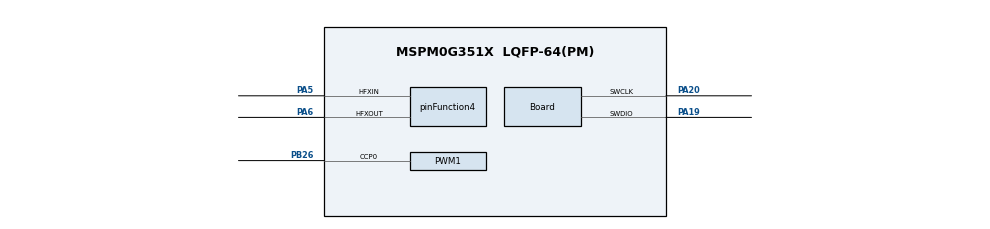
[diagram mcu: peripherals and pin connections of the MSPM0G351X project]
/**
 * @cliArgs --device "MSPM0G351X" --part "Default" --package "LQFP-64(PM)" --product "mspm0_sdk@2.05.01.01"
 * @versions {"tool":"1.24.0+4110"}
 */
const PWM    = scripting.addModule("/ti/driverlib/PWM", {}, false);
const PWM1   = PWM.addInstance();
const SYSCTL = scripting.addModule("/ti/driverlib/SYSCTL");
const TIMER  = scripting.addModule("/ti/driverlib/TIMER", {}, false);
const TIMER1 = TIMER.addInstance();

/* 80 MHz clock */
SYSCTL.forceDefaultClkConfig = true;
SYSCTL.clockTreeEn           = true;
scripting.suppress("For best practices when the CPUCLK is running at 32MHz and above, clear the flash status bit using DL_FlashCTL_executeClearStatus\\(\\) before executing any flash operation\\. Otherwise there may be false positives\\.", SYSCTL);
const divider9       = system.clockTree["UDIV"];
divider9.divideValue = 2;
const multiplier2         = system.clockTree["PLL_QDIV"];
multiplier2.multiplyValue = 4;
const mux4       = system.clockTree["EXHFMUX"];
mux4.inputSelect = "EXHFMUX_XTAL";
const mux8       = system.clockTree["HSCLKMUX"];
mux8.inputSelect = "HSCLKMUX_SYSPLL0";
const mux12       = system.clockTree["SYSPLLMUX"];
mux12.inputSelect = "zSYSPLLMUX_HFCLK";
const pinFunction4                        = system.clockTree["HFXT"];
pinFunction4.inputFreq                    = 40;
pinFunction4.enable                       = true;
pinFunction4.HFXTStartup                  = 10;
pinFunction4.HFCLKMonitor                 = true;
pinFunction4.peripheral.$assign           = "SYSCTL";
pinFunction4.peripheral.hfxInPin.$assign  = "PA5";
pinFunction4.peripheral.hfxOutPin.$assign = "PA6";

const Board                       = scripting.addModule("/ti/driverlib/Board", {}, false);
Board.peripheral.$assign          = "DEBUGSS";
Board.peripheral.swclkPin.$assign = "PA20";
Board.peripheral.swdioPin.$assign = "PA19";

/* WS2812: TIMA1 CCP0 on PB26, 80 MHz clock, period 100 */
PWM1.$name                              = "WS2812";
PWM1.pwmMode                            = "EDGE_ALIGN_UP";
PWM1.ccIndex                            = [0];
PWM1.timerCount                         = 100;
PWM1.timerStartTimer                    = true;
PWM1.peripheral.$assign                 = "TIMA1";
PWM1.peripheral.ccp0Pin.$assign         = "PB26";
PWM1.ccp0PinConfig.direction            = scripting.forceWrite("OUTPUT");
PWM1.ccp0PinConfig.hideOutputInversion  = scripting.forceWrite(false);
PWM1.ccp0PinConfig.onlyInternalResistor = scripting.forceWrite(false);
PWM1.ccp0PinConfig.passedPeripheralType = scripting.forceWrite("Digital");
PWM1.PWM_CHANNEL_0.initVal              = "HIGH";
PWM1.PWM_CHANNEL_0.shadowUpdateMode     = "ZERO_EVT";

/* System tick: TIMA0 5ms */
TIMER1.timerClkDiv        = 8;
TIMER1.timerClkPrescale   = 10;
TIMER1.timerStartTimer    = true;
TIMER1.timerMode          = "PERIODIC";
TIMER1.interrupts         = ["ZERO"];
TIMER1.interruptPriority  = "3";
TIMER1.$name              = "TIMER_TICK";
TIMER1.timerPeriod        = "5 ms";
TIMER1.peripheral.$assign = "TIMA0";

const ProjectConfig              = scripting.addModule("/ti/project_config/ProjectConfig", {}, false);
ProjectConfig.migrationCondition = true;
